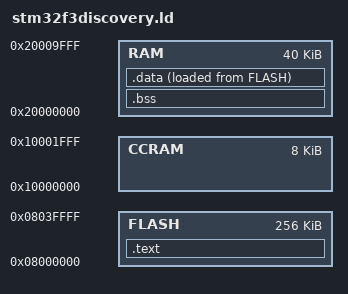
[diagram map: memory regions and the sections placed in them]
MEMORY
{
  CCRAM : ORIGIN = 0x10000000, LENGTH = 8K
  FLASH : ORIGIN = 0x08000000, LENGTH = 256K
  RAM : ORIGIN = 0x20000000, LENGTH = 40K
}

ENTRY(_reset)

SECTIONS
{
  .text ORIGIN(FLASH) :
  {
    /* Vector table */
    LONG(ORIGIN(RAM) + LENGTH(RAM));
    LONG(_reset + 1);
    KEEP(*(.text.exceptions));
    _eexceptions = .;

    /* Entry point: reset handler */
    _reset = .;
    KEEP(*(.text._reset));

    *(.text.*);
    *(.rodata.*);
  } > FLASH

  .bss : ALIGN(4)
  {
    _sbss = .;
    *(.bss.*);
    _ebss = ALIGN(4);
  } > RAM

  .data : ALIGN(4)
  {
    _sdata = .;
    *(.data.*);
    _edata = ALIGN(4);
  } > RAM AT > FLASH

  _sidata = LOADADDR(.data);

  /DISCARD/ :
  {
    *(.ARM.exidx.*)
  }
}

/* Exceptions */
PROVIDE(_nmi = _default_exception_handler);
PROVIDE(_hard_fault = _default_exception_handler);
PROVIDE(_memmanage_fault = _default_exception_handler);
PROVIDE(_bus_fault = _default_exception_handler);
PROVIDE(_usage_fault = _default_exception_handler);
PROVIDE(_svcall = _default_exception_handler);
PROVIDE(_pendsv = _default_exception_handler);
PROVIDE(_systick = _default_exception_handler);

ASSERT(_eexceptions - ORIGIN(FLASH) == 0x40, "exceptions not linked where expected");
